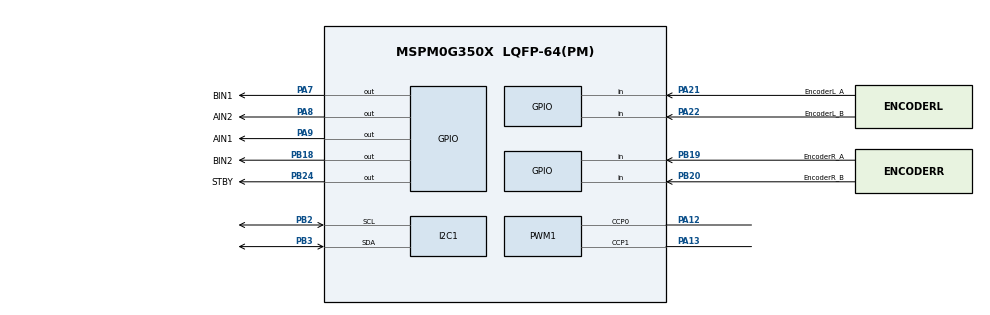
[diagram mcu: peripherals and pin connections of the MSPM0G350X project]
/**
 *
 * @cliArgs --device "MSPM0G350X" --part "Default" --package "LQFP-64(PM)" --product "mspm0_sdk@2.11.00.07"
 * @versions {"tool":"1.28.0+4696"}
 */

/**
 * Import the modules used in this configuration.
 */
const GPIO   = scripting.addModule("/ti/driverlib/GPIO", {}, false);
const GPIO1  = GPIO.addInstance();
const GPIO2  = GPIO.addInstance();
const I2C    = scripting.addModule("/ti/driverlib/I2C", {}, false);
const I2C1   = I2C.addInstance();
const PWM    = scripting.addModule("/ti/driverlib/PWM", {}, false);
const PWM1   = PWM.addInstance();
const SYSCTL = scripting.addModule("/ti/driverlib/SYSCTL");
const TIMER  = scripting.addModule("/ti/driverlib/TIMER", {}, false);
const TIMER1 = TIMER.addInstance();

/**
 * Write custom configuration values to the imported modules.
 */
GPIO1.$name                         = "GPIO_Motor";
GPIO1.associatedPins.create(5);
GPIO1.associatedPins[0].$name       = "AIN1";
GPIO1.associatedPins[0].pin.$assign = "PA9";
GPIO1.associatedPins[1].$name       = "AIN2";
GPIO1.associatedPins[1].pin.$assign = "PA8";
GPIO1.associatedPins[2].$name       = "BIN1";
GPIO1.associatedPins[2].pin.$assign = "PA7";
GPIO1.associatedPins[3].$name       = "BIN2";
GPIO1.associatedPins[3].pin.$assign = "PB18";
GPIO1.associatedPins[4].$name       = "STBY";
GPIO1.associatedPins[4].pin.$assign = "PB24";

const Board = scripting.addModule("/ti/driverlib/Board", {}, false);

GPIO2.$name                              = "GPIO_Encoder";
GPIO2.associatedPins.create(4);
GPIO2.associatedPins[0].$name            = "EncoderL_A";
GPIO2.associatedPins[0].direction        = "INPUT";
GPIO2.associatedPins[0].interruptEn      = true;
GPIO2.associatedPins[0].polarity         = "RISE";
GPIO2.associatedPins[0].internalResistor = "PULL_UP";
GPIO2.associatedPins[0].pin.$assign      = "PA21";
GPIO2.associatedPins[1].$name            = "EncoderL_B";
GPIO2.associatedPins[1].direction        = "INPUT";
GPIO2.associatedPins[1].internalResistor = "PULL_UP";
GPIO2.associatedPins[1].pin.$assign      = "PA22";
GPIO2.associatedPins[2].$name            = "EncoderR_A";
GPIO2.associatedPins[2].direction        = "INPUT";
GPIO2.associatedPins[2].interruptEn      = true;
GPIO2.associatedPins[2].polarity         = "RISE";
GPIO2.associatedPins[2].internalResistor = "PULL_UP";
GPIO2.associatedPins[2].pin.$assign      = "PB19";
GPIO2.associatedPins[3].$name            = "EncoderR_B";
GPIO2.associatedPins[3].direction        = "INPUT";
GPIO2.associatedPins[3].internalResistor = "PULL_UP";
GPIO2.associatedPins[3].pin.$assign      = "PB20";

I2C1.$name                           = "I2C_0";
I2C1.basicEnableController           = true;
I2C1.basicControllerStandardBusSpeed = "Fast";
I2C1.intController                   = ["NACK","TXFIFO_TRIGGER","TX_DONE"];
I2C1.peripheral.$assign              = "I2C1";
I2C1.peripheral.sdaPin.$assign       = "PB3";
I2C1.peripheral.sclPin.$assign       = "PB2";
I2C1.sdaPinConfig.$name              = "ti_driverlib_gpio_GPIOPinGeneric2";
I2C1.sclPinConfig.$name              = "ti_driverlib_gpio_GPIOPinGeneric3";

PWM1.$name                              = "PWM_Motors";
PWM1.pwmMode                            = "EDGE_ALIGN_UP";
PWM1.clockDivider                       = 4;
PWM1.peripheral.$assign                 = "TIMG0";
PWM1.peripheral.ccp0Pin.$assign         = "PA12";
PWM1.peripheral.ccp1Pin.$assign         = "PA13";
PWM1.PWM_CHANNEL_0.$name                = "ti_driverlib_pwm_PWMTimerCC0";
PWM1.PWM_CHANNEL_1.$name                = "ti_driverlib_pwm_PWMTimerCC1";
PWM1.ccp0PinConfig.direction            = scripting.forceWrite("OUTPUT");
PWM1.ccp0PinConfig.hideOutputInversion  = scripting.forceWrite(false);
PWM1.ccp0PinConfig.onlyInternalResistor = scripting.forceWrite(false);
PWM1.ccp0PinConfig.passedPeripheralType = scripting.forceWrite("Digital");
PWM1.ccp0PinConfig.$name                = "ti_driverlib_gpio_GPIOPinGeneric0";
PWM1.ccp1PinConfig.direction            = scripting.forceWrite("OUTPUT");
PWM1.ccp1PinConfig.hideOutputInversion  = scripting.forceWrite(false);
PWM1.ccp1PinConfig.onlyInternalResistor = scripting.forceWrite(false);
PWM1.ccp1PinConfig.passedPeripheralType = scripting.forceWrite("Digital");
PWM1.ccp1PinConfig.$name                = "ti_driverlib_gpio_GPIOPinGeneric1";

SYSCTL.MCLKSource      = "HSCLK";
SYSCTL.HSCLKSource     = "SYSPLLCLK2X";
SYSCTL.SYSPLL_CLK2XEn  = true;
SYSCTL.SYSPLL_CLK2XDiv = 3;

TIMER1.$name              = "TIM_CTRL";
TIMER1.interrupts         = ["ZERO"];
TIMER1.timerMode          = "PERIODIC";
TIMER1.timerClkDiv        = 8;
TIMER1.timerPeriod        = "5 ms";
TIMER1.peripheral.$assign = "TIMG7";

/**
 * Pinmux solution for unlocked pins/peripherals. This ensures that minor changes to the automatic solver in a future
 * version of the tool will not impact the pinmux you originally saw.  These lines can be completely deleted in order to
 * re-solve from scratch.
 */
Board.peripheral.$suggestSolution          = "DEBUGSS";
Board.peripheral.swclkPin.$suggestSolution = "PA20";
Board.peripheral.swdioPin.$suggestSolution = "PA19";
SYSCTL.peripheral.$suggestSolution         = "SYSCTL";
